# SAM9X60D1G_SOM device description
Architecture: ARM926EJ-S; Family: SAM9; Series: SAM9X6
Registers are 32-bit, read-write, no defined reset value unless marked. A register's access mark holds for its fields unless they carry their own. Offsets are from the block's base; [hi:lo] are bit positions.

## RSTC — Reset Controller
Instances: RSTC 0xFFFFFE00
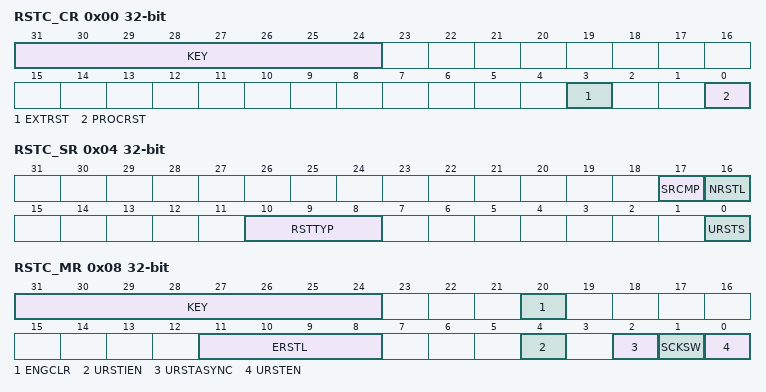
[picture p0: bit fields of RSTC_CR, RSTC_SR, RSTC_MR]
0x00 RSTC_CR wo — Control Register
  [31:24] KEY — System Reset Key
    165=PASSWD (Writing any other value in this field aborts the write operation.)
  [3] EXTRST — External Reset
  [0] PROCRST — Processor Reset
0x04 RSTC_SR ro — Status Register
  [17] SRCMP — Software Reset Command in Progress
  [16] NRSTL — NRST Pin Level
  [10:8] RSTTYP — Reset Type
    0=GENERAL_RST (First powerup reset); 1=BACKUP_RST (Return from Backup mode); 2=WDT_RST (Watchdog fault occurred); 3=SOFT_RST (Processor reset required by the software); 4=USER_RST (NRST pin detected low); 7=SLCK_XTAL_RST (32.768 kHz crystal failure detection fault occurred)
  [0] URSTS — User Reset Status
0x08 RSTC_MR — Mode Register
  [31:24] KEY — Write Access Password
    165=PASSWD (Writing any other value in this field aborts the write operation. Always reads as 0.)
  [20] ENGCLR — Enable GPBR Clear on Tamper Event
  [11:8] ERSTL — External Reset Length
  [4] URSTIEN — User Reset Interrupt Enable
  [2] URSTASYNC — User Reset Asynchronous Control
  [1] SCKSW — Slow Clock Switching
  [0] URSTEN — User Reset Enable

## RTT — Real-time Timer
Instances: RTT 0xFFFFFE20
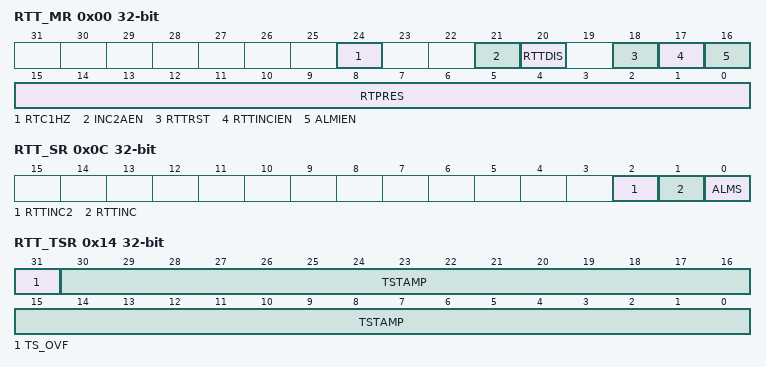
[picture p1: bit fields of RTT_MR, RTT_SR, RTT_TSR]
0x00 RTT_MR — Mode Register
  [24] RTC1HZ — Real-Time Clock 1Hz Clock Selection
  [21] INC2AEN — RTTINC2 Alarm and Interrupt Enable
  [20] RTTDIS — Real-time Timer Disable
  [18] RTTRST — Real-time Timer Restart
  [17] RTTINCIEN — Real-time Timer Increment Interrupt Enable
  [16] ALMIEN — Alarm Interrupt Enable
  [15:0] RTPRES — Real-time Timer Prescaler Value
0x04 RTT_AR — Alarm Register
  [31:0] ALMV — Alarm Value
0x08 RTT_VR ro — Value Register
  [31:0] CRTV — Current Real-time Value
0x0C RTT_SR ro — Status Register
  [2] RTTINC2 — Predefined Number of Prescaler Roll-overs Status (cleared on read)
  [1] RTTINC — Prescaler Roll-over Status (cleared on read)
  [0] ALMS — Real-time Alarm Status (cleared on read)
0x10 RTT_MODR — Modulo Selection Register
  [2:0] SELINC2 — Selection of the 32-bit Counter Modulo to generate RTTINC2 Flag
    0=NO_RTTINC2 (The RTTINC2 flag never rises); 1=MOD64 (The RTTINC2 flag is set when CRTV modulo 64 equals 0); 2=MOD128 (The RTTINC2 flag is set when CRTV modulo 128 equals 0); 3=MOD256 (The RTTINC2 flag is set when CRTV modulo 256 equals 0); 4=MOD512 (The RTTINC2 flag is set when CRTV modulo 512 equals 0); 5=MOD1024 (The RTTINC2 flag is set when CRTV modulo 1024 equals 0. Example: If RTPRES=32 then RTTINC2 flag rises once per second if the slow clock is 32.768 kHz.); 6=MOD2048 (The RTTINC2 flag is set when CRTV modulo 2048 equals 0); 7=MOD4096 (The RTTINC2 flag is set when CRTV modulo 4096 equals 0)
0x14 RTT_TSR ro — TimeStamp Register
  [31] TS_OVF — Timestamp Overflow
  [30:0] TSTAMP — Real-time Timer Value Timestamp

## SCKC — Slow Clock Controller
Instances: SCKC 0xFFFFFE50
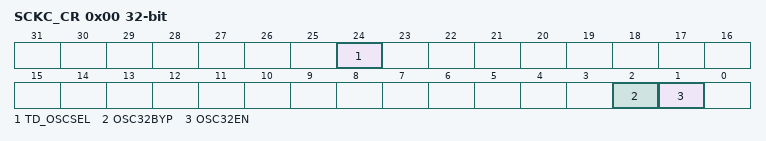
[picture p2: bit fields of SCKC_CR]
0x00 SCKC_CR — Slow Clock Controller Configuration Register
  [24] TD_OSCSEL — Timing Domain Slow Clock Selector
    0=RC (Slow clock of the timing domain is driven by the embedded 32 kHz (typical) RC oscillator.); 1=XTAL (Slow clock of the timing domain is driven by the 32.768 kHz crystal oscillator.)
  [2] OSC32BYP — 32.768 kHz Crystal Oscillator Bypass
  [1] OSC32EN — 32.768 kHz Crystal Oscillator

## SFR — Special Function Registers
Instances: SFR 0xF8050000
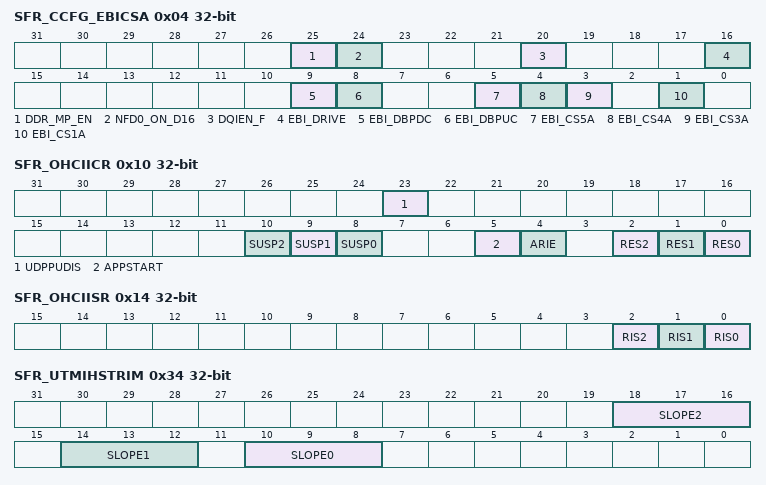
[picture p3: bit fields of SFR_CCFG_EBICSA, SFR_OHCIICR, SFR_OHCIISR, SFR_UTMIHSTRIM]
0x04 SFR_CCFG_EBICSA — EBI Chip Select Register
  [25] DDR_MP_EN — DDR Multi-port Enable
  [24] NFD0_ON_D16 — NAND Flash Databus Selection
  [20] DQIEN_F — Force Analog Input Comparator Configuration
  [16] EBI_DRIVE — EBI I/O Drive Configuration
  [9] EBI_DBPDC — EBI Data Bus Pulldown Configuration
  [8] EBI_DBPUC — EBI Data Bus Pullup Configuration
  [5] EBI_CS5A — EBI Chip Select 5 Assignment
  [4] EBI_CS4A — EBI Chip Select 4 Assignment
  [3] EBI_CS3A — EBI Chip Select 3 Assignment
  [1] EBI_CS1A — EBI Chip Select 1 Assignment
0x10 SFR_OHCIICR — OHCI Interrupt Configuration Register
  [23] UDPPUDIS — Reserved
  [10] SUSP2 — USB PORTx
  [9] SUSP1 — USB PORTx
  [8] SUSP0 — USB PORTx
  [5] APPSTART — Reserved
  [4] ARIE — OHCI Asynchronous Resume Interrupt Enable
  [2] RES2 — USB PORTx Reset
  [1] RES1 — USB PORTx Reset
  [0] RES0 — USB PORTx Reset
0x14 SFR_OHCIISR ro — OHCI Interrupt Status Register
  [2] RIS2 — OHCI Resume Interrupt Status Port 2
  [1] RIS1 — OHCI Resume Interrupt Status Port 1
  [0] RIS0 — OHCI Resume Interrupt Status Port 0
0x34 SFR_UTMIHSTRIM — UTMI High-Speed Trimming Register
  [18:16] SLOPE2 — UTMI HS PORTx Transceiver Slope Trimming
  [14:12] SLOPE1 — UTMI HS PORTx Transceiver Slope Trimming
  [10:8] SLOPE0 — UTMI HS PORTx Transceiver Slope Trimming
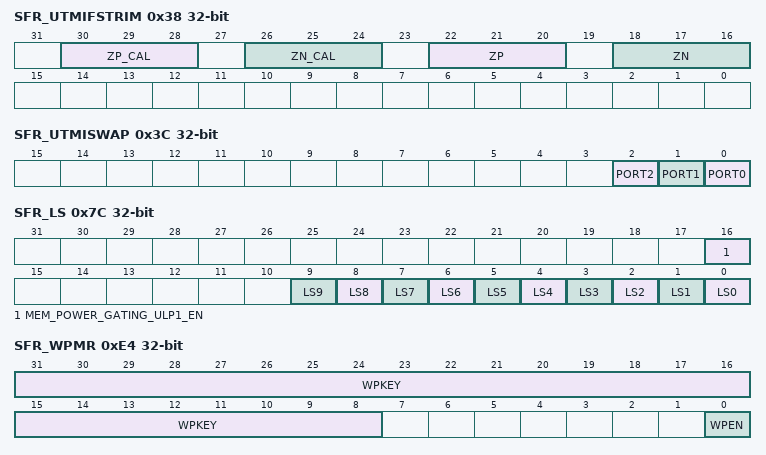
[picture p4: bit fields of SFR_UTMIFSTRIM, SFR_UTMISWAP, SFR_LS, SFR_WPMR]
0x38 SFR_UTMIFSTRIM — UTMI Full-Speed Trimming Register
  [30:28] ZP_CAL — FS Transceiver PMOS Impedance Calibration
  [26:24] ZN_CAL — FS Transceiver NMOS Impedance Calibration
  [22:20] ZP — FS Transceiver PMOS Impedance Trimming
  [18:16] ZN — FS Transceiver NMOS Impedance Trimming
0x3C SFR_UTMISWAP — UTMI DP/DM Pin Swapping Register
  [all] fields
    0=NORMAL (DP/DM normal pinout.); 1=SWAPPED (DP/DM swapped pinout.)
  [2] PORT2 — PORT 2 DP/DM Pin Swapping
  [1] PORT1 — PORT 1 DP/DM Pin Swapping
  [0] PORT0 — PORT 0 DP/DM Pin Swapping
0x7C SFR_LS — Light Sleep Register
  [16] MEM_POWER_GATING_ULP1_EN — Light Sleep Value for ULP1 Power-Gated Memories
  [9] LS9 — Light Sleep Value (ARM926)
  [8] LS8 — Light Sleep Value (ROM + OTPC)
  [7] LS7 — Light Sleep Value (SRAM1 (OTPC))
  [6] LS6 — Light Sleep Value (SRAM0)
  [5] LS5 — Light Sleep Value (EHCI/OHCI)
  [4] LS4 — Light Sleep Value (HXDMA)
  [3] LS3 — Light Sleep Value (HUSB)
  [2] LS2 — Light Sleep Value (SDMMC)
  [1] LS1 — Light Sleep Value (HLCDC5)
  [0] LS0 — Light Sleep Value (GFX2D)
0xE4 SFR_WPMR — Write Protection Mode Register
  [31:8] WPKEY — Write Protection Key
    0x534652=PASSWD (Writing any other value in this field aborts the write operation of the WPEN bit. Always reads as 0.)
  [0] WPEN — Write Protection Enable
